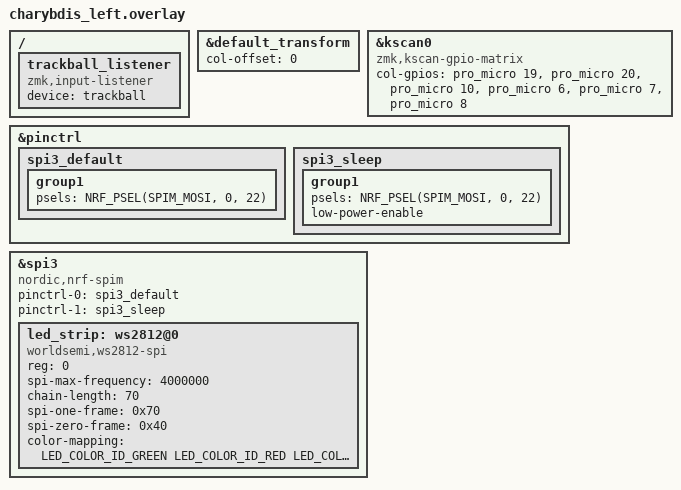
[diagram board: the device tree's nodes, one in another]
/*
 * Copyright (c) 2020 ZMK Contributors
 *
 * SPDX-License-Identifier: MIT
 */

#include <dt-bindings/led/led.h>
#include "charybdis.dtsi"
#include "charybdis_3610.dtsi"
#include "split_input_common.dtsi"

/* Ensure the transform uses the left-side column offset (0) so the physical
 * matrix maps as the left half. */
&default_transform {
    col-offset = <0>;
};

&kscan0 {
	compatible = "zmk,kscan-gpio-matrix";
	
	col-gpios
		= <&pro_micro 19 (GPIO_ACTIVE_HIGH | GPIO_PULL_DOWN)>,
		  <&pro_micro 20 (GPIO_ACTIVE_HIGH | GPIO_PULL_DOWN)>,
		  <&pro_micro 10 (GPIO_ACTIVE_HIGH | GPIO_PULL_DOWN)>,
		  <&pro_micro 6  (GPIO_ACTIVE_HIGH | GPIO_PULL_DOWN)>,
		  <&pro_micro 7  (GPIO_ACTIVE_HIGH | GPIO_PULL_DOWN)>,
		  <&pro_micro 8  (GPIO_ACTIVE_HIGH | GPIO_PULL_DOWN)>;
};

/* SPI / LED strip (same as right overlay) */
&pinctrl {
    spi3_default: spi3_default {
        group1 {
            psels = <NRF_PSEL(SPIM_MOSI, 0, 22)>;
        };
    };

    spi3_sleep: spi3_sleep {
        group1 {
            psels = <NRF_PSEL(SPIM_MOSI, 0, 22)>;
            low-power-enable;
        };
    };
};

&spi3 {
  compatible = "nordic,nrf-spim";
  status = "okay";

  pinctrl-0 = <&spi3_default>;
  pinctrl-1 = <&spi3_sleep>;
  pinctrl-names = "default", "sleep";

  led_strip: ws2812@0 {
    compatible = "worldsemi,ws2812-spi";

    /* SPI */
    reg = <0>; /* ignored, but necessary for SPI bindings */
    spi-max-frequency = <4000000>;

    /* WS2812 */
    chain-length = <70>; /* number of LEDs */
    spi-one-frame = <0x70>;
    spi-zero-frame = <0x40>;
    color-mapping = <LED_COLOR_ID_GREEN
                          LED_COLOR_ID_RED
                          LED_COLOR_ID_BLUE>;
  };
};

/ {
  /* Enable the trackball listener here so the trackball is active on the left half.
   * This points the listener at the trackball device declared in charybdis_3610.dtsi.
   */
  trackball_listener {
    compatible = "zmk,input-listener";
    status = "okay";
    device = <&trackball>;
  };
};
